# MCAN register map
Vendor: Texas Instruments
Registers are 32-bit, access per field, reset 0x0 unless marked. A register's access mark holds for its fields unless they carry their own. Offsets are as the file gives them; [hi:lo] are bit positions.

## MCAN (part 2 of 2)
0x42C01900 MCANSS_PID ro reset not defined — Revision Register The Revision Register contains the major and minor revisions for the module.
  [31:0] REVISION — MCAN revision version
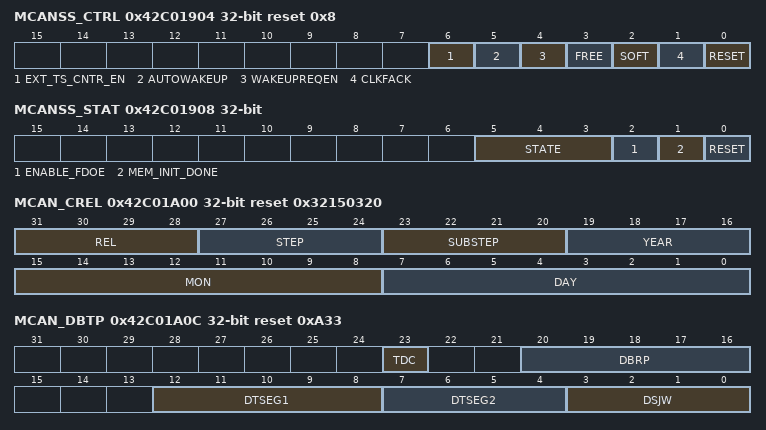
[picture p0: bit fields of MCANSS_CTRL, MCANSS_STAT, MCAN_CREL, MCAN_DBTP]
0x42C01904 MCANSS_CTRL reset 0x8 — Control Register The Control Register contains general control bits for the MCAN module.
  [6] EXT_TS_CNTR_EN rw — External Timestamp Counter Enable
  [5] AUTOWAKEUP rw — Automatic Wakeup Enable
  [4] WAKEUPREQEN rw — Wakeup Request Enable
  [3] FREE rw — 0x0: Disregard debug suspend 0x1: Enable Debug Suspend
  [2] SOFT rw — If FREE = 0x1: 0x0: debug suspend doesn't wait for Idle 0x1: debug suspend waits for Idle
  [1] CLKFACK rw — Clock Fast Ack
  [0] RESET wo — Initiates a Soft Reset Note: Software application should complete all pending MCAN services before applying the soft reset. Accesses to MCAN core registers will be stalled until soft reset is completed.
0x42C01908 MCANSS_STAT ro (reset mask 0xFFFFFFFB) — Status Regsiter The Status register provide general status bits for the MCAN module.
  [5:3] STATE — 0x0: Active 0x1: In transition to Idle 0x2: Idle 0x3: In transition to Active
  [2] ENABLE_FDOE — Enable CAN FD configuration
  [1] MEM_INIT_DONE — 0x0: Memory Initialization is in progress 0x1: Memory Intialization Done
  [0] RESET — 0x0: Not in reset 0x1: Reset is in progress
0x42C0190C MCANSS_ICS — Interrupt Clear Shadow Register Write to clear interrupt bits.
  [0] EXT_TS_CNTR_OVFL wo — External Timestamp Counter Overflow Interrupt status. Write 1 to clear bits.
0x42C01910 MCANSS_IRS access not given — Interrupt Raw Status Register Read raw interrupt status. Write 1 to set interrupt bits.
  [0] EXT_TS_CNTR_OVFL — External Timestamp Counter Overflow Interrupt status. (access RW1TS)
0x42C01914 MCANSS_IECS — Interrupt Enable Clear Shadow Register Write to clear interrupt enable bits.
  [0] EXT_TS_CNTR_OVFL wo — External Timestamp Counter Overflow Interrupt. Write 1 to clear bits.
0x42C01918 MCANSS_IE access not given — Interrupt Enable Register Read interrupt Enable.
  [0] EXT_TS_CNTR_OVFL — External Timestamp Counter Overflow Interrupt. (access RW1TS)
0x42C0191C MCANSS_IES ro — Interrupt Enable Status Read Enabled Interrupts.
  [0] EXT_TS_CNTR_OVFL — External Timestamp Counter Overflow Interrupt.
0x42C01920 MCANSS_EOI — End Of Interrupt End of Interrupt Register.
  [7:0] EOI wo — Write with bit position of targetted interrupt (example: External TS is bit 0). Upon write, level interrupt will clear and if unserviced interrupt counter &gt; 1 will issue another pulse interrupt.
0x42C01924 MCANSS_EXT_TS_PRESCALER — External Timestamp PreScaler 0 External TImeStamp PreScaler.
  [23:0] PRESCALER rw — External Timestamp Prescaler reload value. External Timestamp count rate is Host clock (MCAN_ICLK) rate divided by this vlaue.
0x42C01928 MCANSS_EXT_TS_UNSERVICED_INTR_CNTR ro — External Timestamp PreScaler 0 Unserviced Interrupts Counter External TImeStamp Unserviced Interrupts Counter.
  [4:0] EXT_TS_INTR_CNTR — Number of unserviced rollover interupts. If &gt; 1 an EOI write will issue another pulse interrupt.
0x42C01980 MCANSS_ECC_EOI — ECC EOI End Of Interrupt for ECC interrupt.
  [8] ECC_EOI wo
0x42C01A00 MCAN_CREL ro reset 0x32150320 — Core Release Register Release dependent constant (version + date).
  [31:28] REL — Core Release One digit, BCD-coded.
  [27:24] STEP — Step of Core Release One digit, BCD-coded.
  [23:20] SUBSTEP — Sub-step of Core Release One digit, BCD-coded.
  [19:16] YEAR — Time Stamp Year One digit, BCD-coded.
  [15:8] MON — Time Stamp Month Two digits, BCD-coded.
  [7:0] DAY — Time Stamp Day Two digits, BCD-coded.
0x42C01A04 MCAN_ENDN ro reset 0x87654321 — Endian Register Constant 0x8765 4321.
  [31:0] ETV — Endianness Test Value The endianness test value is 0x8765 4321.
0x42C01A0C MCAN_DBTP reset 0xA33 — Data Bit Timing & Prescaler Register Configuration of data phase bit timing, transmitter delay compensation enable. This register is only writable if the The Therefore the length of the bit time is (programmed values) [
  [23] TDC rw — Transmitter Delay Compensation 0x0: Transmitter Delay Compensation disabled 0x1: Transmitter Delay Compensation enabled
  [20:16] DBRP rw — Data Baud Rate Prescaler The value by which the oscillator frequency is divided for generating the bit time quanta. The bit time is built up from a multiple of this quanta. Valid values for the Baud Rate Prescaler are 0 to 31 (0x00-0x1F). The actual interpretation by the hardware of this value is such that one more than the value programmed here is used.
  [12:8] DTSEG1 rw — Data time segment before sample point Valid values are 0 to 31 (0x00-0x1F). The actual interpretation by the hardware of this value is such that one more than the programmed value is used.
  [7:4] DTSEG2 rw — Data time segment after sample point Valid values are 0 to 15 (0x0-0xF). The actual interpretation by the hardware of this value is such that one more than the programmed value is used.
  [3:0] DSJW rw — Data (Re)Synchronization Jump Width Valid values are 0 to 15 (0x0-0xF). The actual interpretation by the hardware of this value is such that one more than the value programmed here is used.
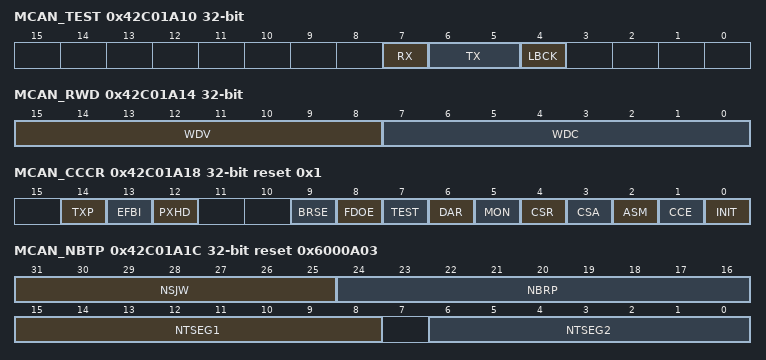
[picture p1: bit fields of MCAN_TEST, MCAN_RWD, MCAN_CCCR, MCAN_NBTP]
0x42C01A10 MCAN_TEST — Test Register Test mode selection. Write access to the Test Register has to be enabled by setting the Loop Back Mode and software control of the MCAN_TX pin are hardware test modes. Programming of the
  [7] RX ro — Receive Pin Monitors the actual value of the MCAN_RX pin 0x0: The CAN bus is dominant (MCAN_RX = 0) 0x1: The CAN bus is recessive (MCAN_RX = 1)
  [6:5] TX rw — Control of Transmit Pin 0x0: Reset value, the MCAN_TX pin controlled by the CAN Core, updated at the end of the CAN bit time 0x1: Sample Point can be monitored at the MCAN_TX pin 0x2: Dominant (0) level at the MCAN_TX pin 0x3: Recessive (1) at the MCAN_TX pin
  [4] LBCK rw — Loop Back Mode 0x0: Reset value, Loop Back Mode is disabled 0x1: Loop Back Mode is enabled
0x42C01A14 MCAN_RWD — RAM Watchdog Monitors the READY output of the Message RAM. The RAM Watchdog monitors the READY output of the Message RAM. A Message RAM access starts the Message RAM Watchdog Counter with the value configured by the
  [15:8] WDV ro — Watchdog Value Actual Message RAM Watchdog Counter Value.
  [7:0] WDC rw — Watchdog Configuration Start value of the Message RAM Watchdog Counter. With the reset value of 00 the counter is disabled.
0x42C01A18 MCAN_CCCR reset 0x1 — CC Control Register Operation mode configuration. For details about setting and resetting of single bits, see
  [14] TXP rw — Transmit Pause If this bit is set, the MCAN module pauses for two CAN bit times before starting the next transmission after itself has successfully transmitted a frame 0x0: Transmit pause disabled 0x1: Transmit pause enabled
  [13] EFBI rw — Edge Filtering during Bus Integration 0x0: Edge filtering disabled 0x1: Two consecutive dominant t
  [12] PXHD rw — Protocol Exception Handling Disable 0x0: Protocol exception handling enabled 0x1: Protocol exception handling disabled
  [9] BRSE rw — Bit Rate Switch Enable 0x0: Bit rate switching for transmissions disabled 0x1: Bit rate switching for transmissions enabled
  [8] FDOE rw — FD Operation Enable 0x0: FD operation disabled 0x1: FD operation enabled
  [7] TEST rw — Test Mode Enable 0x0: Normal operation. The 0x1: Test Mode. Write access to the
  [6] DAR rw — Disable Automatic Retransmission 0x0: Automatic retransmission of messages not transmitted successfully enabled 0x1: Automatic retransmission disabled
  [5] MON rw — Bus Monitoring Mode The 0x0: Bus Monitoring Mode is disabled 0x1: Bus Monitoring Mode is enabled
  [4] CSR rw — Clock Stop Request 0x0: No clock stop is requested 0x1: Clock stop requested. When clock stop is requested, first the
  [3] CSA ro — Clock Stop Acknowledge 0x0: No clock stop acknowledged 0x1: The MCAN module may be set in power down by stopping MCAN_ICLK and MCAN_FCLK
  [2] ASM rw — Restricted Operation Mode The 0x0: Normal CAN operation 0x1: Restricted Operation Mode active
  [1] CCE rw — Configuration Change Enable 0x0: The Host CPU has no write access to the protected configuration registers 0x1: The Host CPU has write access to the protected configuration registers (while the
  [0] INIT rw — Initialization 0x0: Normal Operation 0x1: Initialization is started
0x42C01A1C MCAN_NBTP reset 0x6000A03 — Nominal Bit Timing & Prescaler Register Configuration of arbitration phase bit timing. This register is only writable if the Therefore the length of the bit time is (programmed values) [ The Information Processing Time (IPT) is zero, meaning the data for the next bit is available at the first clock edge after the sample point.
  [31:25] NSJW rw — Nominal (Re)Synchronization Jump Width Valid values are 0 to 127 (0x00-0x7F). The actual interpretation by the hardware of this value is such that one more than the value programmed here is used.
  [24:16] NBRP rw — Nominal Baud Rate Prescaler The value by which the oscillator frequency is divided for generating the bit time quanta. The bit time is built up from a multiple of this quanta. Valid values for the Baud Rate Prescaler are 0 to 511 (0x000-0x1FF). The actual interpretation by the hardware of this value is such that one more than the value programmed here is used.
  [15:8] NTSEG1 rw — Nominal Time segment before sample point Valid values are 1 to 255 (0x01-0xFF). The actual interpretation by the hardware of this value is such that one more than the programmed value is used.
  [6:0] NTSEG2 rw — Nominal Time segment after sample point Valid values are 0 to 127 (0x00-0x7F). The actual interpretation by the hardware of this value is such that one more than the programmed value is used.
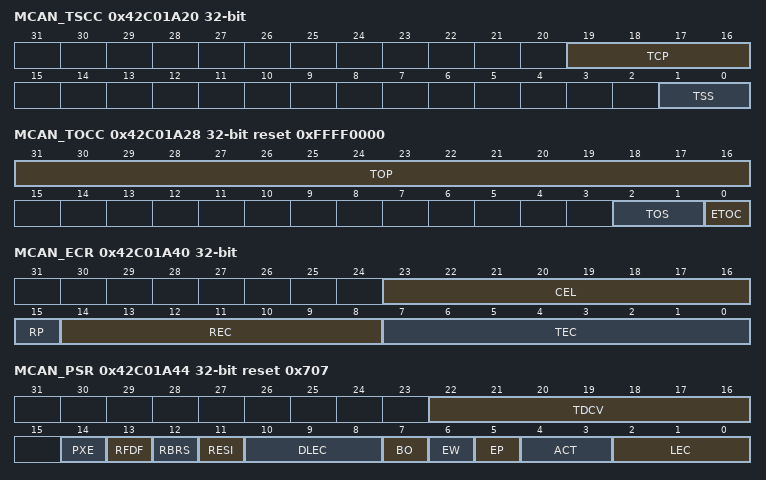
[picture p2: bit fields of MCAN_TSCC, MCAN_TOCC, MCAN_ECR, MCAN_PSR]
0x42C01A20 MCAN_TSCC — Timestamp Counter Configuration Timestamp counter prescaler setting, selection of internal/external timestamp vector. For a description of the Timestamp Counter, see
  [19:16] TCP rw — Timestamp Counter Prescaler Configures the timestamp and timeout counters time unit in multiples of CAN bit times [1-16 (0x0-0xF)]. The actual interpretation by the hardware of this value is such that one more than the value programmed here is used.
  [1:0] TSS rw — Timestamp Select 0x0: Timestamp counter value always 0x0000 0x1: Timestamp counter value incremented according to the 0x2: External timestamp counter value used 0x3: Same as 00
0x42C01A24 MCAN_TSCV access not given — Timestamp Counter Value Read/reset timestamp counter.
  [15:0] TSC — Timestamp Counter The internal/external Timestamp Counter value is captured on start of frame (both Rx and Tx). When the [1-16] depending on the configuration of the Write access resets the counter to zero. When the (access RWTC)
0x42C01A28 MCAN_TOCC reset 0xFFFF0000 — Timeout Counter Configuration Configuration of timeout period, selection of timeout counter operation mode. For a description of the Timeout Counter, see
  [31:16] TOP rw — Timeout Period Start value of the Timeout Counter (down-counter). Configures the Timeout Period.
  [2:1] TOS rw — Timeout Select When operating in Continuous mode, a write to the 0x0: Continuous operation 0x1: Timeout controlled by Tx Event FIFO 0x2: Timeout controlled by Rx FIFO 0 0x3: Timeout controlled by Rx FIFO 1
  [0] ETOC rw — Enable Timeout Counter 0x0: Timeout Counter disabled 0x1: Timeout Counter enabled
0x42C01A2C MCAN_TOCV access not given reset 0xFFFF — Timeout Counter Value Read/reset timeout counter.
  [15:0] TOC — Timeout Counter The Timeout Counter is decremented in multiples of CAN bit times [1-16] depending on the configuration of the (access RWTC)
0x42C01A40 MCAN_ECR ro — Error Counter Register State of Rx/Tx Error Counter, CAN Error Logging.
  [23:16] CEL — CAN Error Logging The counter is incremented each time when a CAN protocol error causes the Transmit Error Counter or the Receive Error Counter to be incremented. It is reset by read access to the
  [15] RP — Receive Error Passive 0x0: The Receive Error Counter is below the error passive level of 128 0x1: The Receive Error Counter has reached the error passive level of 128
  [14:8] REC — Receive Error Counter Actual state of the Receive Error Counter, values between 0 and 127.
  [7:0] TEC — Transmit Error Counter Actual state of the Transmit Error Counter, values between 0 and 255.
0x42C01A44 MCAN_PSR ro reset 0x707 — Protocol Status Register CAN protocol controller status, transmitter delay compensation value.
  [22:16] TDCV — Transmitter Delay Compensation Value Position of the secondary sample point, defined by the sum of the measured delay from the MCAN_TX to MCAN_RX pins and the
  [14] PXE — Protocol Exception Event 0x0: No protocol exception event occurred since last read access 0x1: Protocol exception event occurred
  [13] RFDF — Received a CAN FD Message This bit is set independent of acceptance filtering. 0x0: Since this bit was reset by the Host CPU, no CAN FD message has been received 0x1: Message in CAN FD format with FDF flag set has been received
  [12] RBRS — BRS flag of last received CAN FD Message This bit is set together with the 0x0: Last received CAN FD message did not have its BRS flag set 0x1: Last received CAN FD message had its BRS flag set
  [11] RESI — ESI flag of last received CAN FD Message This bit is set together with the 0x0: Last received CAN FD message did not have its ESI flag set 0x1: Last received CAN FD message had its ESI flag set
  [10:8] DLEC — Data Phase Last Error Code Type of last error that occurred in the data phase of a CAN FD format frame with its BRS flag set. Coding is the same as for the
  [7] BO — Bus_Off Status 0x0: The MCAN module is not Bus_Off 0x1: The MCAN module is in Bus_Off state
  [6] EW — Warning Status 0x0: Both error counters are below the Error_Warning limit of 96 0x1: At least one of error counter has reached the Error_Warning limit of 96
  [5] EP — Error Passive 0x0: The MCAN module is in the Error_Active state. It normally takes part in bus communication and sends an active error flag when an error has been detected 0x1: The MCAN module is in the Error_Passive state
  [4:3] ACT — Activity Monitors the module's CAN communication state. 0x0: Synchronizing - node is synchronizing on CAN communication 0x1: Idle - node is neither receiver nor transmitter 0x2: Receiver - node is operating as receiver 0x3: Transmitter - node is operating as transmitter
  [2:0] LEC — Last Error Code The 0x0: No Error: No error occurred since the 0x1: Stuff Error: More than 5 equal bits in a sequence have occurred in a part of a received message where this is not allowed. 0x2: Form Error: A fixed format part of a received frame has the wrong format. 0x3: AckError: The message transmitted by the MCAN module was not acknowledged by another node. 0x4: Bit1Error: During the transmission of a message (with the exception of the arbitration field), the device wanted to send a recessive level (bit of logical value 1), but the monitored bus value was dominant. 0x5: Bit0Error: During the transmission of a message (or acknowledge bit, or active error flag, or overload flag), the device wanted to send a dominant level (data or identifier bit logical value 0), but the monitored bus value was recessive. During Bus_Off recovery this status is set each time a sequence of 11 recessive bits has been monitored. This enables the Host CPU to monitor the proceeding of the Bus_Off recovery sequence (indicating the bus is not stuck at dominant or continuously disturbed). 0x6: CRCError: The CRC check sum of a received message was incorrect. The CRC of an incom-ing message does not match with the CRC calculated from the received data. 0x7: NoChange: Any read access to the Protocol Status Register re-initializes the
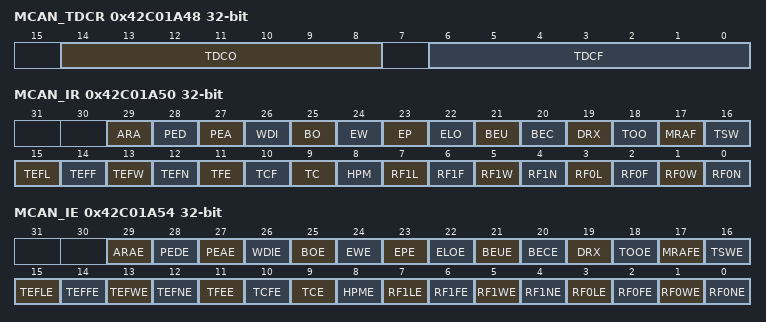
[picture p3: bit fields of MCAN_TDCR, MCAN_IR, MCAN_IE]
0x42C01A48 MCAN_TDCR — Transmitter Delay Comensation Register Configuration of transmitter delay compensation offset and filter window length.
  [14:8] TDCO rw — Transmitter Delay Compensation Offset Offset value defining the distance between the measured delay from the MCAN_RX and MCAN_TX pins and the secondary sample point. Valid values are 0 to 127 mtq (0x00-0x7F).
  [6:0] TDCF rw — Transmitter Delay Compensation Filter Window Length Defines the minimum value for the SSP position, dominant edges on the MCAN_RX pin that would result in an earlier SSP position are ignored for transmitter delay measure-ment. The feature is enabled when the
0x42C01A50 MCAN_IR access not given — Interrupt RegisterThe flags are set when one of the listed conditions is detected (edge-sensitive). The flags remain set until the Host CPU clears them. A flag is cleared by writing a 1 to the corresponding bit position. Writing a 0 has no effect. A hard reset will clear the register. The configuration of the
  [29] ARA — Access to Reserved Address 0x0: No access to reserved address occurred 0x1: Access to reserved address occurred (access RW1TC)
  [28] PED — Protocol Error in Data Phase 0x0: No protocol error in data phase 0x1: Protocol error in data phase detected ( (access RW1TC)
  [27] PEA — Protocol Error in Arbitration Phase 0x0: No protocol error in arbitration phase 0x1: Protocol error in arbitration phase detected ( (access RW1TC)
  [26] WDI — Watchdog Interrupt 0x0: No Message RAM Watchdog event occurred 0x1: Message RAM Watchdog event due to missing READY (access RW1TC)
  [25] BO — Bus_Off Status 0x0: Bus_Off status unchanged 0x1: Bus_Off status changed (access RW1TC)
  [24] EW — Warning Status 0x0: Error_Warning status unchanged 0x1: Error_Warning status changed (access RW1TC)
  [23] EP — Error Passive 0x0: Error_Passive status unchanged 0x1: Error_Passive status changed (access RW1TC)
  [22] ELO — Error Logging Overflow 0x0: CAN Error Logging Counter did not overflow 0x1: Overflow of CAN Error Logging Counter occurred (access RW1TC)
  [21] BEU — Bit Error Uncorrected Message RAM bit error detected, uncorrected. Controlled by input signal generated by parity/ECC logic attached to the Message RAM. An uncorrected Message RAM bit error sets the 0x0: No bit error detected when reading from Message RAM 0x1: Bit error detected, uncorrected (example: parity logic) (access RW1TC)
  [20] BEC — Bit Error Corrected Message RAM bit error detected and corrected. Controlled by input signal generated by parity/ECC logic attached to the Message RAM. 0x0: No bit error detected when reading from Message RAM 0x1: Bit error detected and corrected (example: ECC) (access RW1TC)
  [19] DRX — Message stored to Dedicated Rx Buffer The flag is set whenever a received message has been stored into a dedicated Rx Buffer. 0x0: No Rx Buffer updated 0x1: At least one received message stored into an Rx Buffer (access RW1TC)
  [18] TOO — Timeout Occurred 0x0: No timeout 0x1: Timeout reached (access RW1TC)
  [17] MRAF — Message RAM Access Failure The flag is set, when the Rx Handler: • has not completed acceptance filtering or storage of an accepted message until the arbitration field of the following message has been received. In this case acceptance filtering or message storage is aborted and the Rx Handler starts processing of the following message. • was not able to write a message to the Message RAM. In this case message storage is aborted. In both cases the FIFO put index is not updated respectively the New Data flag for a dedicated Rx Buffer is not set, a partly stored message is overwritten when the next message is stored to this location. The flag is also set when the Tx Handler was not able to read a message from the Message RAM in time. In this case message transmission is aborted. In case of a Tx Handler access failure the MCAN module is switched into Restricted Operation Mode (see 0x0: No Message RAM access failure occurred 0x1: Message RAM access failure occurred (access RW1TC)
  [16] TSW — Timestamp Wraparound 0x0: No timestamp counter wrap-around 0x1: Timestamp counter wrapped around (access RW1TC)
  [15] TEFL — Tx Event FIFO Element Lost 0x0: No Tx Event FIFO element lost 0x1: Tx Event FIFO element lost, also set after write attempt to Tx Event FIFO of size zero (access RW1TC)
  [14] TEFF — Tx Event FIFO Full 0x0: Tx Event FIFO not full 0x1: Tx Event FIFO full (access RW1TC)
  [13] TEFW — Tx Event FIFO Watermark Reached 0x0: Tx Event FIFO fill level below watermark 0x1: Tx Event FIFO fill level reached watermark (access RW1TC)
  [12] TEFN — Tx Event FIFO New Entry 0x0: Tx Event FIFO unchanged 0x1: Tx Handler wrote Tx Event FIFO element (access RW1TC)
  [11] TFE — Tx FIFO Empty 0x0: Tx FIFO non-empty 0x1: Tx FIFO empty (access RW1TC)
  [10] TCF — Transmission Cancellation Finished 0x0: No transmission cancellation finished 0x1: Transmission cancellation finished (access RW1TC)
  [9] TC — Transmission Completed 0x0: No transmission completed 0x1: Transmission completed (access RW1TC)
  [8] HPM — High Priority Message 0x0: No high priority message received 0x1: High priority message received (access RW1TC)
  [7] RF1L — Rx FIFO 1 Message Lost 0x0: No Rx FIFO 1 message lost 0x1: Rx FIFO 1 message lost, also set after write attempt to Rx FIFO 1 of size zero (access RW1TC)
  [6] RF1F — Rx FIFO 1 Full 0x0: Rx FIFO 1 not full 0x1: Rx FIFO 1 full (access RW1TC)
  [5] RF1W — Rx FIFO 1 Watermark Reached 0x0: Rx FIFO 1 fill level below watermark 0x1: Rx FIFO 1 fill level reached watermark (access RW1TC)
  [4] RF1N — Rx FIFO 1 New Message 0x0: No new message written to Rx FIFO 1 0x1: New message written to Rx FIFO 1 (access RW1TC)
  [3] RF0L — Rx FIFO 0 Message Lost 0x0: No Rx FIFO 0 message lost 0x1: Rx FIFO 0 message lost, also set after write attempt to Rx FIFO 0 of size zero (access RW1TC)
  [2] RF0F — Rx FIFO 0 Full 0x0: Rx FIFO 0 not full 0x1: Rx FIFO 0 full (access RW1TC)
  [1] RF0W — Rx FIFO 0 Watermark Reached 0x0: Rx FIFO 0 fill level below watermark 0x1: Rx FIFO 0 fill level reached watermark (access RW1TC)
  [0] RF0N — Rx FIFO 0 New Message 0x0: No new message written to Rx FIFO 0 0x1: New message written to Rx FIFO 0 (access RW1TC)
0x42C01A54 MCAN_IE — Interrupt EnableThe settings in the Interrupt Enable register determine which status changes in the Interrupt Register are signalled on an interrupt line.
  [29] ARAE rw — Access to Reserved Address Enable 0x0: Interrupt disabled 0x1: Interrupt enabled
  [28] PEDE rw — Protocol Error in Data Phase Enable 0x0: Interrupt disabled 0x1: Interrupt enabled
  [27] PEAE rw — Protocol Error in Arbitration Phase Enable 0x0: Interrupt disabled 0x1: Interrupt enabled
  [26] WDIE rw — Watchdog Interrupt Enable 0x0: Interrupt disabled 0x1: Interrupt enabled
  [25] BOE rw — Bus_Off Status Interrupt Enable 0x0: Interrupt disabled 0x1: Interrupt enabled
  [24] EWE rw — Warning Status Interrupt Enable 0x0: Interrupt disabled 0x1: Interrupt enabled
  [23] EPE rw — Error Passive Interrupt Enable 0x0: Interrupt disabled 0x1: Interrupt enabled
  [22] ELOE rw — Error Logging Overflow Interrupt Enable 0x0: Interrupt disabled 0x1: Interrupt enabled
  [21] BEUE rw — Bit Error Uncorrected Interrupt Enable 0x0: Interrupt disabled 0x1: Interrupt enabled
  [20] BECE rw — Bit Error Corrected Interrupt Enable 0x0: Interrupt disabled 0x1: Interrupt enabled
  [19] DRX rw — Message stored to Dedicated Rx Buffer Interrupt Enable
  [18] TOOE rw — Timeout Occurred Interrupt Enable 0x0: Interrupt disabled 0x1: Interrupt enabled
  [17] MRAFE rw — Message RAM Access Failure Interrupt Enable 0x0: Interrupt disabled 0x1: Interrupt enabled
  [16] TSWE rw — Timestamp Wraparound Interrupt Enable 0x0: Interrupt disabled 0x1: Interrupt enabled
  [15] TEFLE rw — Tx Event FIFO Event Lost Interrupt Enable 0x0: Interrupt disabled 0x1: Interrupt enabled
  [14] TEFFE rw — Tx Event FIFO Full Interrupt Enable 0x0: Interrupt disabled 0x1: Interrupt enabled
  [13] TEFWE rw — Tx Event FIFO Watermark Reached Interrupt Enable 0x0: Interrupt disabled 0x1: Interrupt enabled
  [12] TEFNE rw — Tx Event FIFO New Entry Interrupt Enable 0x0: Interrupt disabled 0x1: Interrupt enabled
  [11] TFEE rw — Tx FIFO Empty Interrupt Enable 0x0: Interrupt disabled 0x1: Interrupt enabled
  [10] TCFE rw — Transmission Cancellation Finished Interrupt Enable 0x0: Interrupt disabled 0x1: Interrupt enabled
  [9] TCE rw — Transmission Completed Interrupt Enable 0x0: Interrupt disabled 0x1: Interrupt enabled
  [8] HPME rw — High Priority Message Interrupt Enable 0x0: Interrupt disabled 0x1: Interrupt enabled
  [7] RF1LE rw — Rx FIFO 1 Message Lost Interrupt Enable 0x0: Interrupt disabled 0x1: Interrupt enabled
  [6] RF1FE rw — Rx FIFO 1 Full Interrupt Enable 0x0: Interrupt disabled 0x1: Interrupt enabled
  [5] RF1WE rw — Rx FIFO 1 Watermark Reached Interrupt Enable 0x0: Interrupt disabled 0x1: Interrupt enabled
  [4] RF1NE rw — Rx FIFO 1 New Message Interrupt Enable 0x0: Interrupt disabled 0x1: Interrupt enabled
  [3] RF0LE rw — Rx FIFO 0 Message Lost Interrupt Enable 0x0: Interrupt disabled 0x1: Interrupt enabled
  [2] RF0FE rw — Rx FIFO 0 Full Interrupt Enable 0x0: Interrupt disabled 0x1: Interrupt enabled
  [1] RF0WE rw — Rx FIFO 0 Watermark Reached Interrupt Enable 0x0: Interrupt disabled 0x1: Interrupt enabled
  [0] RF0NE rw — Rx FIFO 0 New Message Interrupt Enable 0x0: Interrupt disabled 0x1: Interrupt enabled
